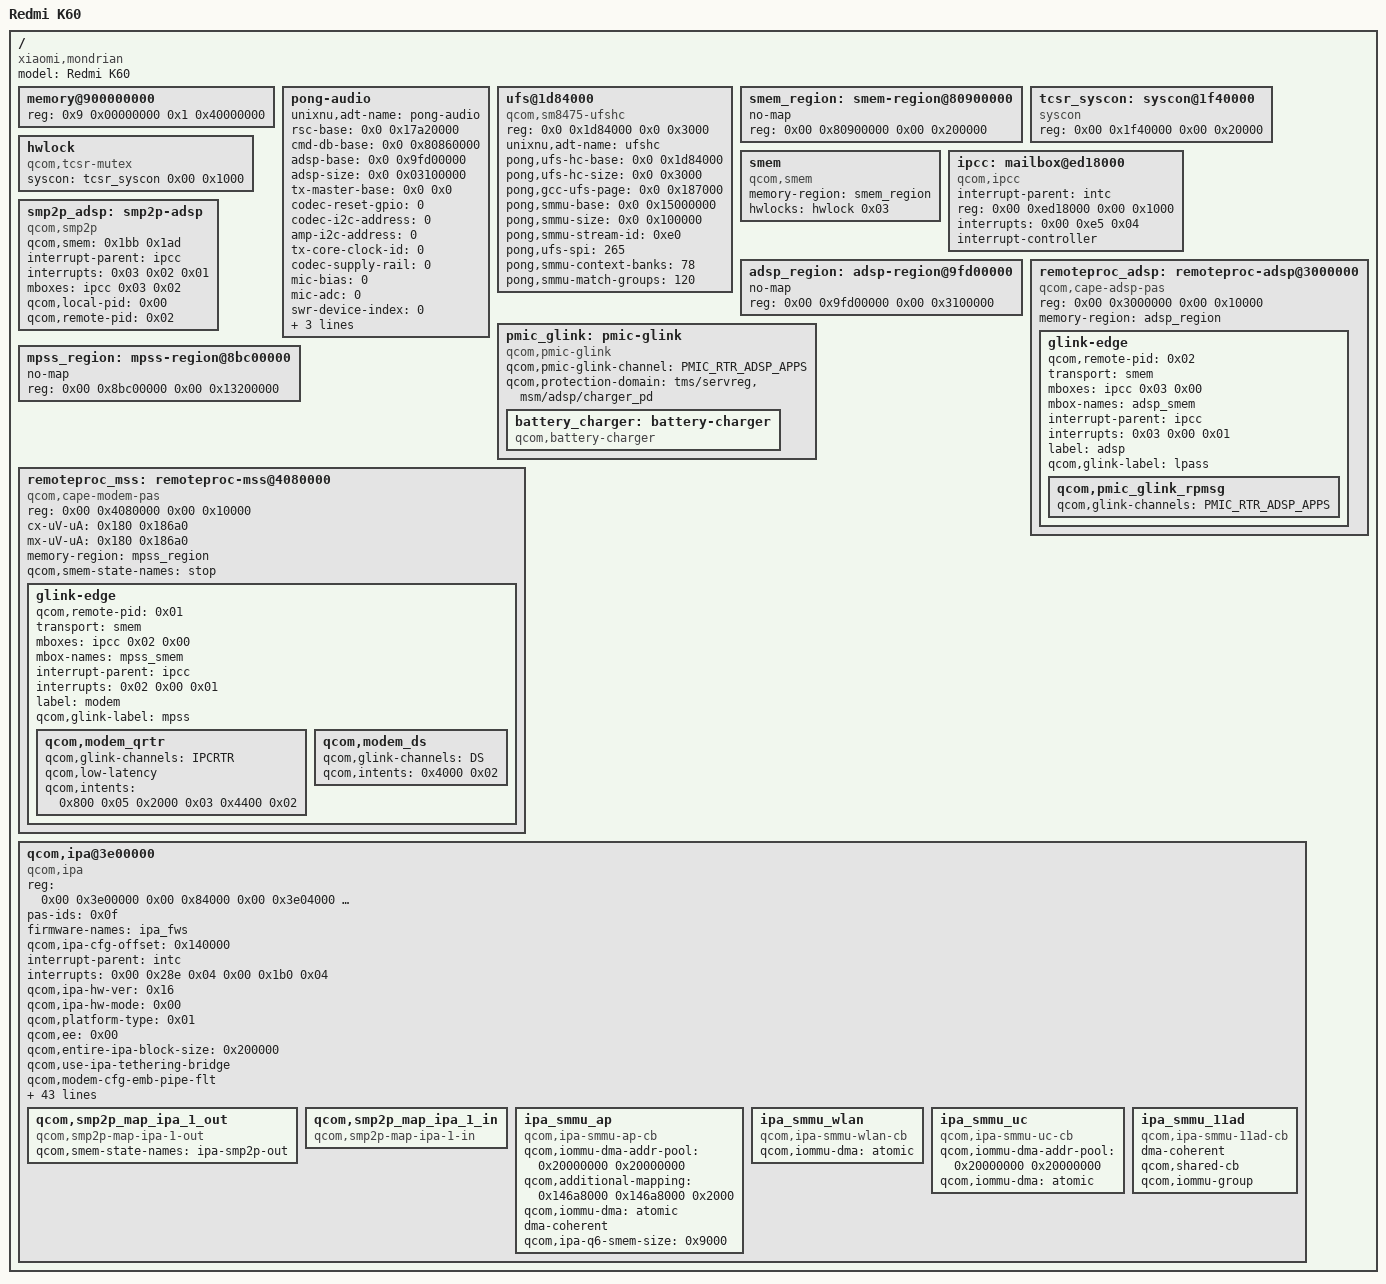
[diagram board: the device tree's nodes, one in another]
/dts-v1/;

/*
 * Redmi K60 (mondrian) board description.
 *
 * The SM8475 CPUs, PSCI conduit and GICv3 window come from the SoC source; this
 * file adds what is specific to the board. The Apple identity and the OS
 * properties come from the OS profile's [adt] tables, and the payload handoff
 * options from board.toml [payload.adt].
 */

/include/ "sm8475.dtsi"

/ {
	model = "Redmi K60";
	compatible = "xiaomi,mondrian";

	/*
	 * UniXNU contiguous handoff arena, NOT a claim about total installed RAM.
	 * Serial 6033dbec live Android /memory/reg and /proc/iomem (2026-11-02) put
	 * Serial 6033dbec live Android /memory/reg and /proc/iomem (2026-11-02) put
	 * the only long high run at 0x840000000..0xa80000000 (9 GiB). A 7 GiB window
	 * inside it was accepted by the loader but XNU printed nothing, so this image
	 * goes back to the proven 4 GiB geometry: arena [0x900000000,0xa40000000) and
	 * a 4 GiB managed window, which reached XNU with mem=actual=managed=4096 MiB.
	 * The diagnostic kernel is unchanged, so the failing-program list is the goal.
	 * 12 GiB is impossible: 4..32 GiB is a 28 GiB hole and no run is 12 GiB.
	 */
	memory@900000000 {
		device_type = "memory";
		reg = <0x9 0x00000000 0x1 0x40000000>;
	};

	/*
	 * SM8475 UFS host (NativeUfs.cpp window checks: NativeUfs.cpp kUfsHost /
	 * kGccUfsPage / SMMU constants, pong,ufs-* / pong,smmu-* properties are
	 * exported to the ADT via unixnu,adt-name).
	 */


	/*
	 * Audio hardware exported to the ADT. Every value here is either an SM8475
	 * address window the existing nodes already use, or zero.
	 *
	 * Zero means "not measured yet", never "use a default": the driver must
	 * refuse to start and name the missing property. Guessing an I2C address, a
	 * GPIO or a clock id produces a device that reports success and makes no
	 * sound, which is the hardest failure to read from a log.
	 *
	 * Non-zero sources: rsc-base and cmd-db-base are shared with pong-touch
	 * above; adsp-base is the SM8475 ADSP window from Pong's PAS1 work;
	 * timebase-hz is 19.2 MHz, as on SM8550.
	 */
	pong-audio {
		unixnu,adt-name = "pong-audio";
		rsc-base = <0x0 0x17a20000>;
		cmd-db-base = <0x0 0x80860000>;
		adsp-base = <0x0 0x9fd00000>;
		adsp-size = <0x0 0x03100000>;

		/* 0 = not measured. The driver must reject these and say which one. */
		tx-master-base = <0x0 0x0>;
		codec-reset-gpio = <0>;
		codec-i2c-address = <0>;
		amp-i2c-address = <0>;
		tx-core-clock-id = <0>;
		codec-supply-rail = <0>;
		mic-bias = <0>;
		mic-adc = <0>;
		swr-device-index = <0>;

		/* CoreAudio assumes 24 MHz. At a 19.2 MHz timebase the audio service
		 * must correct that constant, or the IO period runs 25% long and both
		 * playback and capture stutter. */
		timebase-hz = <19200000>;
		coreaudio-assumed-hz = <24000000>;

		/* Periodic buffers must sit below 4 GiB: the DSP takes a 32-bit
		 * address with the stream index in the high word (0x1001 & 0xf). */
		period-buffer-limit = <0x1 0x00000000>;
	};

	ufs@1d84000 {
		compatible = "qcom,sm8475-ufshc";
		status = "okay";
		reg = <0x0 0x1d84000 0x0 0x3000>;
		unixnu,adt-name = "ufshc";
		pong,ufs-hc-base = <0x0 0x1d84000>;
		pong,ufs-hc-size = <0x0 0x3000>;
		pong,gcc-ufs-page = <0x0 0x187000>;
		pong,smmu-base = <0x0 0x15000000>;
		pong,smmu-size = <0x0 0x100000>;
		pong,smmu-stream-id = <0xe0>;
		pong,ufs-spi = <265>;
		pong,smmu-context-banks = <78>;
		pong,smmu-match-groups = <120>;
	};

	/*
	 * The CPU nodes come from the SoC dtsi: eight cores with the flat
	 * 0x000..0x700 reg values, which are the hardware MPIDRs (Aff1 = core
	 * index). The Android tree carries the same values, this firmware refuses
	 * every CPU_ON target outside that table (bc9), and XNU matches a starting
	 * core to its cpu data by this value - so do not override them here. The
	 * 4/3/1 A510/A710/X2 grouping seen in Android's sysfs is cache topology,
	 * not MPIDR affinity.
	 */
};

/*
 * ADSP / GLINK infrastructure, copied from the official board FDT
 * (Platforms/Xiaomi/mondrianPkg/FdtBlob/sm8475-xiaomi-mondrian.dtb) rather than
 * invented: smem_region@80900000, syscon@1f40000 + tcsr-mutex hwlock,
 * mailboxes@ed18000 (ipcc), the cape-adsp-pas remoteproc and the pmic-glink
 * channel that the battery archive builder requires.  Every reg value and every
 * child property below appears verbatim in that dump; see
 * docs/research/audio/VENDOR-ADSP-NODE.md.
 */
/ {
	smem_region: smem-region@80900000 {
		no-map;
		reg = <0x00 0x80900000 0x00 0x200000>;
	};

	tcsr_syscon: syscon@1f40000 {
		compatible = "syscon";
		reg = <0x00 0x1f40000 0x00 0x20000>;
	};

	hwlock: hwlock {
		compatible = "qcom,tcsr-mutex";
		syscon = <&tcsr_syscon 0x00 0x1000>;
		#hwlock-cells = <0x01>;
	};

	smem: smem {
		compatible = "qcom,smem";
		memory-region = <&smem_region>;
		hwlocks = <&hwlock 0x03>;
	};

	ipcc: mailbox@ed18000 {
		interrupt-parent = <&intc>;
		compatible = "qcom,ipcc";
		reg = <0x00 0xed18000 0x00 0x1000>;
		interrupts = <0x00 0xe5 0x04>;
		interrupt-controller;
		#interrupt-cells = <0x03>;
		#mbox-cells = <0x02>;
	};

	adsp_region: adsp-region@9fd00000 {
		no-map;
		reg = <0x00 0x9fd00000 0x00 0x3100000>;
	};

	remoteproc_adsp: remoteproc-adsp@3000000 {
		compatible = "qcom,cape-adsp-pas";
		reg = <0x00 0x3000000 0x00 0x10000>;
		memory-region = <&adsp_region>;
		status = "ok";

		glink-edge {
			qcom,remote-pid = <0x02>;
			transport = "smem";
			mboxes = <&ipcc 0x03 0x00>;
			mbox-names = "adsp_smem";
			interrupt-parent = <&ipcc>;
			interrupts = <0x03 0x00 0x01>;
			label = "adsp";
			qcom,glink-label = "lpass";

			qcom,pmic_glink_rpmsg {
				qcom,glink-channels = "PMIC_RTR_ADSP_APPS";
			};
		};
	};

	smp2p_adsp: smp2p-adsp {
		compatible = "qcom,smp2p";
		qcom,smem = <0x1bb 0x1ad>;
		interrupt-parent = <&ipcc>;
		interrupts = <0x03 0x02 0x01>;
		mboxes = <&ipcc 0x03 0x02>;
		qcom,local-pid = <0x00>;
		qcom,remote-pid = <0x02>;
	};

	pmic_glink: pmic-glink {
		compatible = "qcom,pmic-glink";
		qcom,pmic-glink-channel = "PMIC_RTR_ADSP_APPS";
		qcom,protection-domain = "tms/servreg", "msm/adsp/charger_pd";

		battery_charger: battery-charger {
			compatible = "qcom,battery-charger";
		};
	};
};

/*
 * Modem, IPA and QRTR infrastructure, for the cellular line.
 *
 * DOCUMENTATION ONLY. None of these nodes carries unixnu,adt-name, so none of
 * them is exported to the ADT, and no XNU driver probes them yet: the tree
 * describes the hardware, the kernel still does not touch it. Boot behaviour is
 * unchanged.
 *
 * Every literal value below is copied from the live Android device tree
 * (/proc/device-tree of serial 6033dbec) and is byte-identical to it. Three
 * mechanical rewrites were unavoidable; each one is enumerated, with the
 * original text, in docs/research/cellular/04-DT-NODES.md:
 *
 *   1. The live tree hangs the modem and IPA nodes under /soc, a 1-cell address
 *      space. This file has no /soc container, so they hang off the root and
 *      their reg properties are widened to the root's two cells
 *      (0x00 <addr> 0x00 <size>), exactly as adsp-region@9fd00000 already is.
 *   2. Phandle references are dropped, because the nodes they point at (the
 *      rpmh clock controller, the PM8350C regulators, apps-smmu, linux,cma,
 *      ipa_gsi_region, smp2p-ipa) do not exist in this reduced tree and a
 *      dangling phandle is a dtc error. The two references this tree can honour
 *      are kept: <&ipcc> and <&mpss_region>. A property whose only content was
 *      such a reference is omitted whole, never with a placeholder value.
 *   3. interrupt-parent = <&intc> is restated on qcom,ipa, because the live tree
 *      inherits it from /soc.
 *
 * There is no status property on any of these nodes on purpose: the firmware
 * has never been started from XNU, so nothing here may claim to be okay.
 */
/ {
	/* /reserved-memory/mpss_region@8bc00000 in the live tree. */
	mpss_region: mpss-region@8bc00000 {
		no-map;
		reg = <0x00 0x8bc00000 0x00 0x13200000>;
	};

	/*
	 * /soc/remoteproc-mss@04080000 in the live tree: the modem subsystem
	 * (MSS) itself, its GLINK edge, and the two GLINK channels on it. The
	 * QRTR channel is qcom,modem_qrtr ("IPCRTR"); qcom,modem_ds is the data
	 * service channel the vendor firmware also opens.
	 *
	 * memory-region names only mpss_region here; the vendor tree also lists
	 * linux,cma in the same property, and this tree has no CMA reservation.
	 *
	 * interrupt-names is kept because it fixes the vendor order of the six
	 * modem interrupts, but interrupts-extended is omitted: five of its six
	 * entries point at smp2p slave-kernel, which this tree does not describe.
	 * The sixth is GIC SPI 0x108.
	 */
	remoteproc_mss: remoteproc-mss@4080000 {
		compatible = "qcom,cape-modem-pas";
		reg = <0x00 0x4080000 0x00 0x10000>;
		clock-names = "xo";
		reg-names = "cx", "mx";
		cx-uV-uA = <0x180 0x186a0>;
		mx-uV-uA = <0x180 0x186a0>;
		interconnect-names = "rproc_ddr", "crypto_ddr";
		memory-region = <&mpss_region>;
		interrupt-names = "wdog", "fatal", "handover", "ready", "stop-ack", "shutdown-ack";
		qcom,smem-state-names = "stop";

		glink-edge {
			qcom,remote-pid = <0x01>;
			transport = "smem";
			mboxes = <&ipcc 0x02 0x00>;
			mbox-names = "mpss_smem";
			interrupt-parent = <&ipcc>;
			interrupts = <0x02 0x00 0x01>;
			label = "modem";
			qcom,glink-label = "mpss";

			qcom,modem_qrtr {
				qcom,glink-channels = "IPCRTR";
				qcom,low-latency;
				qcom,intents = <0x800 0x05 0x2000 0x03 0x4400 0x02>;
			};

			qcom,modem_ds {
				qcom,glink-channels = "DS";
				qcom,intents = <0x4000 0x02>;
			};
		};
	};

	/*
	 * /soc/qcom,ipa@3e00000 in the live tree: the IPA block and its GSI
	 * engine, the firmware name the modem loads for it, the bus vectors, and
	 * the five IPA SMMU context banks.
	 *
	 * Omitted for the reason in note 2: clocks, memory-regions, interconnects,
	 * and every iommus / qcom,smem-states / interrupts-extended inside the
	 * child nodes. qcom,ipa-hw-ver = 0x16 is IPAv4.5 and qcom,ipa-hw-mode = 0
	 * is the GSI mode; both are firmware facts, not configuration.
	 */
	qcom,ipa@3e00000 {
		compatible = "qcom,ipa";
		reg = <0x00 0x3e00000 0x00 0x84000 0x00 0x3e04000 0x00 0xfc000>;
		reg-names = "ipa-base", "gsi-base";
		pas-ids = <0x0f>;
		firmware-names = "ipa_fws";
		qcom,ipa-cfg-offset = <0x140000>;
		interrupt-parent = <&intc>;
		interrupts = <0x00 0x28e 0x04 0x00 0x1b0 0x04>;
		interrupt-names = "ipa-irq", "gsi-irq";
		qcom,ipa-hw-ver = <0x16>;
		qcom,ipa-hw-mode = <0x00>;
		qcom,platform-type = <0x01>;
		qcom,ee = <0x00>;
		qcom,entire-ipa-block-size = <0x200000>;
		qcom,use-ipa-tethering-bridge;
		qcom,modem-cfg-emb-pipe-flt;
		qcom,ipa-wdi3-over-gsi;
		qcom,arm-smmu;
		qcom,smmu-fast-map;
		qcom,use-64-bit-dma-mask;
		qcom,ipa-endp-delay-wa-v2;
		qcom,ipa-ulso-wa;
		qcom,lan-rx-napi;
		qcom,tx-napi;
		qcom,tx-poll;
		qcom,wan-use-skb-page;
		qcom,rmnet-ctl-enable;
		qcom,rmnet-ll-enable;
		qcom,ipa-uc-holb-monitor;
		qcom,ipa-holb-monitor-poll-period = <0x05>;
		qcom,ipa-holb-monitor-max-cnt-wlan = <0x0a>;
		qcom,ipa-holb-monitor-max-cnt-usb = <0x0a>;
		qcom,ipa-holb-monitor-max-cnt-11ad = <0x0a>;
		qcom,register-collection-on-crash;
		qcom,testbus-collection-on-crash;
		qcom,non-tn-collection-on-crash;
		qcom,tx-wrapper-cache-max-size = <0x190>;
		qcom,ipa-gpi-event-rp-ddr;
		qcom,ulso-supported;
		qcom,ulso-ip-id-min-linux-val = <0x00>;
		qcom,ulso-ip-id-max-linux-val = <0xffff>;
		qcom,ulso-ip-id-min-windows-val = <0x00>;
		qcom,ulso-ip-id-max-windows-val = <0x7fff>;
		qcom,max_num_smmu_cb = <0x04>;
		clock-names = "core_clk";
		qcom,interconnect,num-cases = <0x05>;
		qcom,interconnect,num-paths = <0x03>;
		interconnect-names = "ipa_to_llcc", "llcc_to_ebi1", "appss_to_ipa";
		qcom,no-vote = <0x00 0x00 0x00 0x00 0x00 0x00>;
		qcom,svs2 = <0x900b0 0x00 0x900b0 0x1cfde0 0x00 0x12c00>;
		qcom,svs = <0x124f80 0x00 0x124f80 0x2ab980 0x00 0x249f0>;
		qcom,nominal = <0x249f00 0x00 0x249f00 0x53ec60 0x00 0x61a80>;
		qcom,turbo = <0x36ee80 0x00 0x36ee80 0x53ec60 0x00 0x61a80>;
		qcom,bus-vector-names = "MIN", "SVS2", "SVS", "NOMINAL", "TURBO";
		qcom,throughput-threshold = <0x7d0 0xfa0 0x1f40>;
		qcom,scaling-exceptions;

		qcom,smp2p_map_ipa_1_out {
			compatible = "qcom,smp2p-map-ipa-1-out";
			qcom,smem-state-names = "ipa-smp2p-out";
		};

		qcom,smp2p_map_ipa_1_in {
			compatible = "qcom,smp2p-map-ipa-1-in";
			interrupt-names = "ipa-smp2p-in";
		};

		ipa_smmu_ap {
			compatible = "qcom,ipa-smmu-ap-cb";
			qcom,iommu-dma-addr-pool = <0x20000000 0x20000000>;
			qcom,additional-mapping = <0x146a8000 0x146a8000 0x2000>;
			qcom,iommu-dma = "atomic";
			dma-coherent;
			qcom,ipa-q6-smem-size = <0x9000>;
		};

		ipa_smmu_wlan {
			compatible = "qcom,ipa-smmu-wlan-cb";
			qcom,iommu-dma = "atomic";
		};

		ipa_smmu_uc {
			compatible = "qcom,ipa-smmu-uc-cb";
			qcom,iommu-dma-addr-pool = <0x20000000 0x20000000>;
			qcom,iommu-dma = "atomic";
		};

		ipa_smmu_11ad {
			compatible = "qcom,ipa-smmu-11ad-cb";
			dma-coherent;
			qcom,shared-cb;
			qcom,iommu-group;
		};
	};
};
